# STM32L552 register map
File version: 1.5
CPU: CM33 r0p1, little endian, MPU, FPU, 3 interrupt priority bits
Registers are 32-bit, read-write, reset 0x0 unless marked. A register's access mark holds for its fields unless they carry their own. Offsets are from the block's base; [hi:lo] are bit positions; lines under a group give offsets from that group; {n}, {i} and the like mark numbered series.

## LPTIM1 — Low power timer
Base 0x40007C00
Same registers: LPTIM2 0x40009400, LPTIM3 0x40009800, SEC_LPTIM1 0x50007C00, SEC_LPTIM2 0x50009400, SEC_LPTIM3 0x50009800
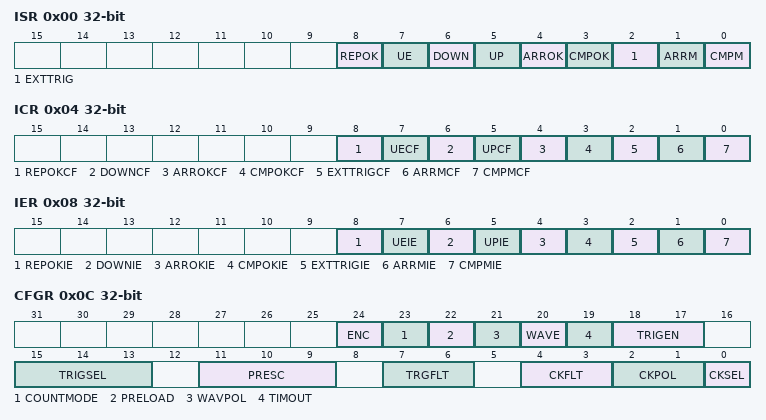
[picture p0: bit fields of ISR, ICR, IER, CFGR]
0x00 ISR ro — Interrupt and Status Register
  [8] REPOK — Repetition register update Ok
  [7] UE — LPTIM update event occurred
  [6] DOWN — Counter direction change up to down
  [5] UP — Counter direction change down to up
  [4] ARROK — Autoreload register update OK
  [3] CMPOK — Compare register update OK
  [2] EXTTRIG — External trigger edge event
  [1] ARRM — Autoreload match
  [0] CMPM — Compare match
0x04 ICR wo — Interrupt Clear Register
  [8] REPOKCF — Repetition register update OK clear flag
  [7] UECF — Update event clear flag
  [6] DOWNCF — Direction change to down Clear Flag
  [5] UPCF — Direction change to UP Clear Flag
  [4] ARROKCF — Autoreload register update OK Clear Flag
  [3] CMPOKCF — Compare register update OK Clear Flag
  [2] EXTTRIGCF — External trigger valid edge Clear Flag
  [1] ARRMCF — Autoreload match Clear Flag
  [0] CMPMCF — compare match Clear Flag
0x08 IER — Interrupt Enable Register
  [8] REPOKIE
  [7] UEIE — Update event interrupt enable
  [6] DOWNIE — Direction change to down Interrupt Enable
  [5] UPIE — Direction change to UP Interrupt Enable
  [4] ARROKIE — Autoreload register update OK Interrupt Enable
  [3] CMPOKIE — Compare register update OK Interrupt Enable
  [2] EXTTRIGIE — External trigger valid edge Interrupt Enable
  [1] ARRMIE — Autoreload match Interrupt Enable
  [0] CMPMIE — Compare match Interrupt Enable
0x0C CFGR — Configuration Register
  [24] ENC — Encoder mode enable
  [23] COUNTMODE — counter mode enabled
  [22] PRELOAD — Registers update mode
  [21] WAVPOL — Waveform shape polarity
  [20] WAVE — Waveform shape
  [19] TIMOUT — Timeout enable
  [18:17] TRIGEN — Trigger enable and polarity
  [15:13] TRIGSEL — Trigger selector
  [11:9] PRESC — Clock prescaler
  [7:6] TRGFLT — Configurable digital filter for trigger
  [4:3] CKFLT — Configurable digital filter for external clock
  [2:1] CKPOL — Clock Polarity
  [0] CKSEL — Clock selector
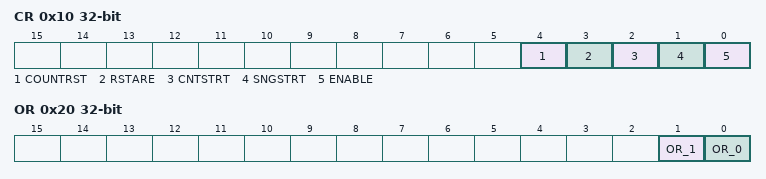
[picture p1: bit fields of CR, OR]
0x10 CR — Control Register
  [4] COUNTRST — Counter reset
  [3] RSTARE — Reset after read enable
  [2] CNTSTRT — Timer start in continuous mode
  [1] SNGSTRT — LPTIM start in single mode
  [0] ENABLE — LPTIM Enable
0x14 CMP — Compare Register
  [15:0] CMP — Compare value
0x18 ARR reset 0x1 — Autoreload Register
  [15:0] ARR — Auto reload value
0x1C CNT ro — Counter Register
  [15:0] CNT — Counter value
0x20 OR — LPTIM option register
  [1] OR_1 — Option register bit 1
  [0] OR_0 — Option register bit 0
0x28 RCR — LPTIM repetition register
  [7:0] REP — Repetition register value

## DMA1 — Direct memory access controller
Base 0x40020000
Same registers: DMA2 0x40020400, SEC_DMA1 0x50020000, SEC_DMA2 0x50020400
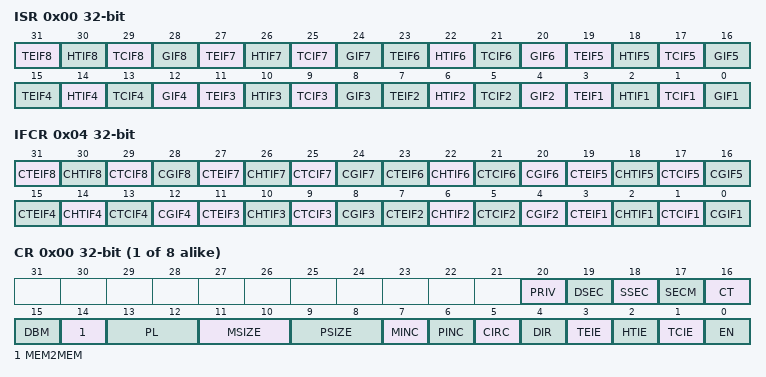
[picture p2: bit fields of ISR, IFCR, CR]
0x00 ISR ro — interrupt status register
  [31] TEIF8 — transfer error (TE) flag for channel 8
  [30] HTIF8 — half transfer (HT) flag for channel 8
  [29] TCIF8 — transfer complete (TC) flag for channel 8
  [28] GIF8 — global interrupt flag for channel 8
  [4n-1] TEIF{n} (n=1..7) — Channel x transfer error flag (x = 1 ..7)
  [4n-2] HTIF{n} (n=1..7) — Channel x half transfer flag (x = 1 ..7)
  [4n-3] TCIF{n} (n=1..7) — Channel x transfer complete flag (x = 1 ..7)
  [4n-4] GIF{n} (n=1..7) — Channel x global interrupt flag (x = 1 ..7)
0x04 IFCR wo — interrupt flag clear register
  [31] CTEIF8 — transfer error flag clear for channel 8
  [30] CHTIF8 — half transfer flag clear for channel 8
  [29] CTCIF8 — transfer complete flag clear for channel 8
  [28] CGIF8 — global interrupt flag clear for channel 8
  [4n-1] CTEIF{n} (n=1..7) — Channel x transfer error clear (x = 1 ..7)
  [4n-2] CHTIF{n} (n=1..7) — Channel x half transfer clear (x = 1 ..7)
  [4n-3] CTCIF{n} (n=1..7) — Channel x transfer complete clear (x = 1 ..7)
  [4n-4] CGIF{n} (n=1..7) — Channel x global interrupt clear (x = 1 ..7)
0x08 CH{i} (i=1..8; step 0x14) group — Channel cluster: CCR?, CNDTR?, CPAR?, CM0AR?, and CM1AR? registers
  0x00 CR — channel x configuration register
    [20] PRIV — privileged mode
    [19] DSEC — security of the DMA transfer to the destination
    [18] SSEC — security of the DMA transfer from the source
    [17] SECM — secure mode
    [16] CT — current target memory of DMA transfer in double-buffer mode
    [15] DBM — double-buffer mode
    [14] MEM2MEM — Memory to memory mode
    [13:12] PL — Channel priority level
    [11:10] MSIZE — Memory size
    [9:8] PSIZE — Peripheral size
    [7] MINC — Memory increment mode
    [6] PINC — Peripheral increment mode
    [5] CIRC — Circular mode
    [4] DIR — Data transfer direction
    [3] TEIE — Transfer error interrupt enable
    [2] HTIE — Half transfer interrupt enable
    [1] TCIE — Transfer complete interrupt enable
    [0] EN — Channel enable
  0x04 NDTR — channel x number of data register
    [17:0] NDT — Number of data to transfer
  0x08 PAR — channel x peripheral address register
    [31:0] PA — Peripheral address
  0x0C M0AR — channel x memory address register
    [31:0] MA — Memory address
  0x10 M1AR — channel x memory address register
    [31:0] MA — peripheral address
0xA8 CSELR — channel selection register
  [31:0] MA — peripheral address
